# ATSAME51J18A register map
Vendor: Microchip Technology; Series: SAME51; File version: 0
CPU: CM4 r0p1, selectable endian, MPU, FPU, 3 interrupt priority bits
Registers are 32-bit, read-write, reset 0x0 unless marked. A register's access mark holds for its fields unless they carry their own. Offsets are from the block's base; [hi:lo] are bit positions; lines under a group give offsets from that group; {n}, {i} and the like mark numbered series; 'fields as' and 'values as' point back to an identical list.

## DMAC — Direct Memory Access Controller
Base 0x4100A000; register names take the prefix DMAC_
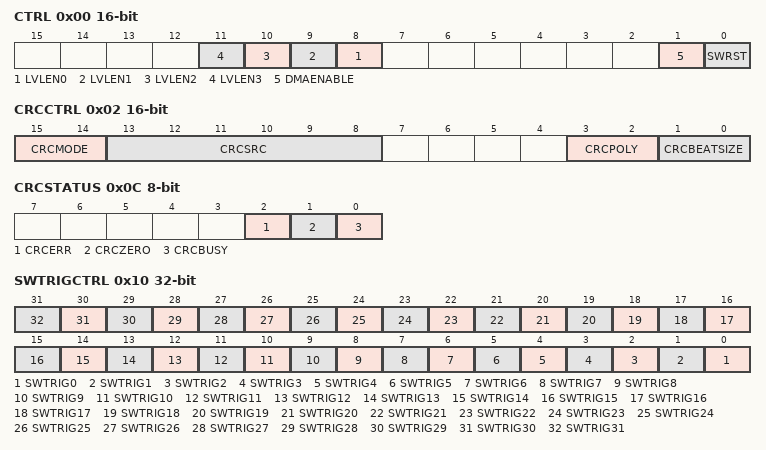
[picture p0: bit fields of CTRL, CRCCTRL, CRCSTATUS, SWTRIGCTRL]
0x00 CTRL 16-bit — Control
  [n+8] LVLEN{n} (n=0..3) — Priority Level {n} Enable
  [1] DMAENABLE
  [0] SWRST — Software Reset
0x02 CRCCTRL 16-bit — CRC Control
  [15:14] CRCMODE — CRC Operating Mode
    0=DEFAULT (Default operating mode); 2=CRCMON (Memory CRC monitor operating mode); 3=CRCGEN (Memory CRC generation operating mode)
  [13:8] CRCSRC — CRC Input Source
    0=DISABLE (CRC Disabled); 1=IO (I/O interface)
  [3:2] CRCPOLY — CRC Polynomial Type
    0=CRC16 (CRC-16 (CRC-CCITT)); 1=CRC32 (CRC32 (IEEE 802.3))
  [1:0] CRCBEATSIZE
    0=BYTE (8-bit bus transfer); 1=HWORD (16-bit bus transfer); 2=WORD (32-bit bus transfer)
0x04 CRCDATAIN — CRC Data Input
  [7:0] CRCDATAIN8 — CRC Data Input
  [15:0] CRCDATAIN16 — CRC Data Input
  [31:0] CRCDATAIN — CRC Data Input
0x08 CRCCHKSUM — CRC Checksum
  [15:0] CRCCHKSUM16 — CRC Checksum
  [31:0] CRCCHKSUM32 — CRC Checksum
0x0C CRCSTATUS 8-bit
  [2] CRCERR ro — CRC Error
  [1] CRCZERO ro
  [0] CRCBUSY write-1-clears — CRC Module Busy
0x0D DBGCTRL 8-bit — Debug Control
  [0] DBGRUN — Debug Run
0x10 SWTRIGCTRL — Software Trigger Control
  [n] SWTRIG{n} (n=0..31) — Channel {n} Software Trigger
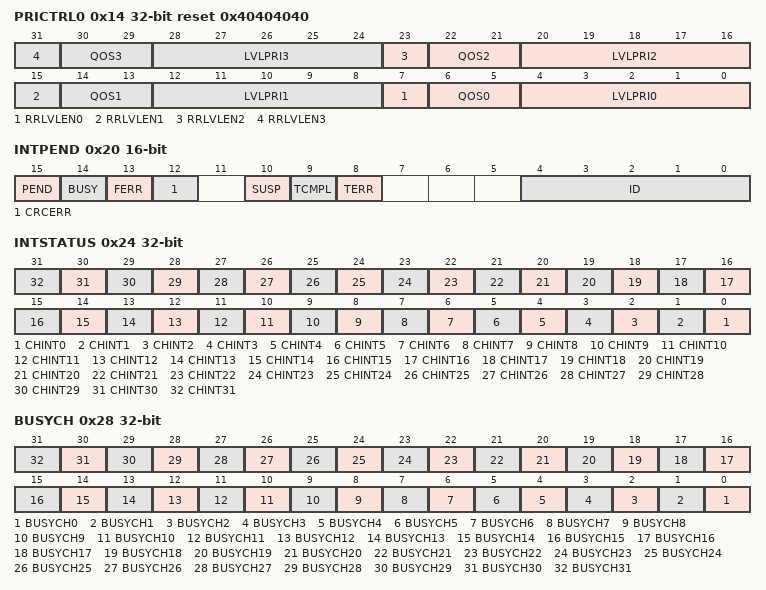
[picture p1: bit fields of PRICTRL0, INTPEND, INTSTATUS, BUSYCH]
0x14 PRICTRL0 reset 0x40404040 — Priority Control 0
  [8n+7] RRLVLEN{n} (n=0..3) — Level {n} Round-Robin Scheduling Enable
  [8n+6:8n+5] QOS{n} (n=0..3) — Level {n} Quality of Service
    0=REGULAR (Regular delivery); 1=SHORTAGE (Bandwidth shortage); 2=SENSITIVE (Latency sensitive); 3=CRITICAL (Latency critical)
  [8n+4:8n] LVLPRI{n} (n=0..3) — Level {n} Channel Priority Number
0x20 INTPEND 16-bit — Interrupt Pending
  [15] PEND ro — Pending
  [14] BUSY ro
  [13] FERR ro — Fetch Error
  [12] CRCERR write-1-clears — CRC Error
  [10] SUSP write-1-clears — Channel Suspend
  [9] TCMPL write-1-clears — Transfer Complete
  [8] TERR write-1-clears — Transfer Error
  [4:0] ID — Channel ID
0x24 INTSTATUS ro — Interrupt Status
  [n] CHINT{n} (n=0..31) — Channel {n} Pending Interrupt
0x28 BUSYCH ro — Busy Channels
  [n] BUSYCH{n} (n=0..31) — Busy Channel {n}
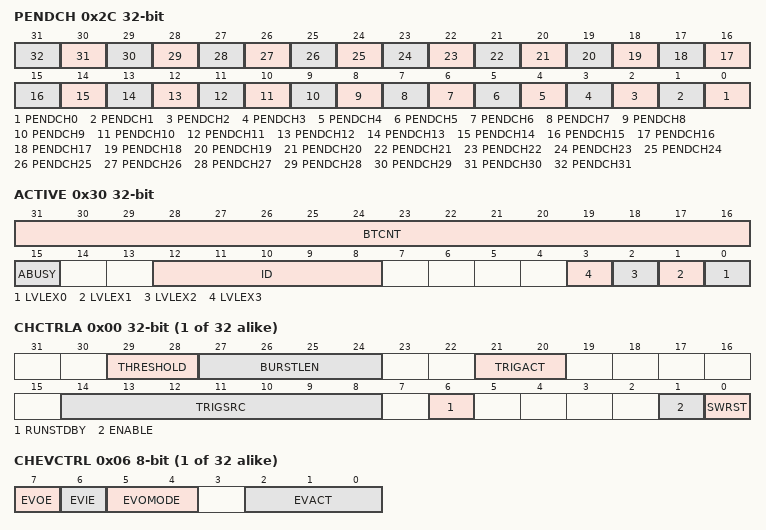
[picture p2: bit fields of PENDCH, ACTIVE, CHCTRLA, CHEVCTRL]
0x2C PENDCH ro — Pending Channels
  [n] PENDCH{n} (n=0..31) — Pending Channel {n}
0x30 ACTIVE ro — Active Channel and Levels
  [31:16] BTCNT — Active Channel Block Transfer Count
  [15] ABUSY — Active Channel Busy
  [12:8] ID — Active Channel ID
  [n] LVLEX{n} (n=0..3) — Level {n} Channel Trigger Request Executing
0x34 BASEADDR — Descriptor Memory Section Base Address
  [31:0] BASEADDR — Descriptor Memory Base Address
0x38 WRBADDR — Write-Back Memory Section Base Address
  [31:0] WRBADDR — Write-Back Memory Base Address
{0x40+0x10*i} CHANNEL[{i}] (i=0..31) group
  0x00 CHCTRLA — Channel n Control A
    [29:28] THRESHOLD — FIFO Threshold
      0=1BEAT (Destination write starts after each beat source address read); 1=2BEATS (Destination write starts after 2-beats source address read); 2=4BEATS (Destination write starts after 4-beats source address read); 3=8BEATS (Destination write starts after 8-beats source address read)
    [27:24] BURSTLEN — Burst Length
      0=SINGLE (Single-beat burst length); {v}={v+1}BEAT ({v+1}-beats burst length) (v=1..15)
    [21:20] TRIGACT — Trigger Action
      0=BLOCK (One trigger required for each block transfer); 2=BURST (One trigger required for each burst transfer); 3=TRANSACTION (One trigger required for each transaction)
    [14:8] TRIGSRC — Trigger Source
      0=DISABLE (Only software/event triggers); 1=RTC_TIMESTAMP (DMA RTC timestamp trigger); 2=DSU_DCC0 (DMAC ID for DCC0 register); 3=DSU_DCC1 (DMAC ID for DCC1 register); 4=SERCOM0_RX (Index of DMA RX trigger); 5=SERCOM0_TX (Index of DMA TX trigger); 6=SERCOM1_RX (Index of DMA RX trigger); 7=SERCOM1_TX (Index of DMA TX trigger); 8=SERCOM2_RX (Index of DMA RX trigger); 9=SERCOM2_TX (Index of DMA TX trigger); 10=SERCOM3_RX (Index of DMA RX trigger); 11=SERCOM3_TX (Index of DMA TX trigger); 12=SERCOM4_RX (Index of DMA RX trigger); 13=SERCOM4_TX (Index of DMA TX trigger); 14=SERCOM5_RX (Index of DMA RX trigger); 15=SERCOM5_TX (Index of DMA TX trigger); 16=SERCOM6_RX (Index of DMA RX trigger); 17=SERCOM6_TX (Index of DMA TX trigger); 18=SERCOM7_RX (Index of DMA RX trigger); 19=SERCOM7_TX (Index of DMA TX trigger); 20=CAN0_DEBUG (DMA CAN Debug Req); 21=CAN1_DEBUG (DMA CAN Debug Req); 22=TCC0_OVF (DMA overflow/underflow/retrigger trigger); {v}=TCC0_MC_{v-23} (Indexes of DMA Match/Compare triggers) (v=23..28); 29=TCC1__OVF_DMA (overflow/underflow/retrigger trigger); {v}=TCC1_MC_{v-30} (Indexes of DMA Match/Compare triggers) (v=30..33); 34=TCC2_OVF (DMA overflow/underflow/retrigger trigger); 35=TCC2_MC_0 (Indexes of DMA Match/Compare triggers); 36=TCC2_MC_1 (Indexes of DMA Match/Compare triggers); 37=TCC2_MC_2 (Indexes of DMA Match/Compare triggers); 38=TCC3_OVF (DMA overflow/underflow/retrigger trigger); 39=TCC3_MC_0 (Indexes of DMA Match/Compare triggers); 40=TCC3_MC_1 (Indexes of DMA Match/Compare triggers); 41=TCC4_OVF (DMA overflow/underflow/retrigger trigger); 42=TCC4_MC_0 (Indexes of DMA Match/Compare triggers); 43=TCC4_MC_1 (Indexes of DMA Match/Compare triggers); 44=TC0_OVF (Indexes of DMA Overflow trigger); 45=TC0_MC_0 (Indexes of DMA Match/Compare triggers); 46=TC0_MC_1 (Indexes of DMA Match/Compare triggers); 47=TC1_OVF (Indexes of DMA Overflow trigger); 48=TC1_MC_0 (Indexes of DMA Match/Compare triggers); 49=TC1_MC_1 (Indexes of DMA Match/Compare triggers); 50=TC2_OVF (Indexes of DMA Overflow trigger); 51=TC2_MC_0 (Indexes of DMA Match/Compare triggers); 52=TC2_MC_1 (Indexes of DMA Match/Compare triggers); 53=TC3_OVF (Indexes of DMA Overflow trigger); 54=TC3_MC_0 (Indexes of DMA Match/Compare triggers); 55=TC3_MC_1 (Indexes of DMA Match/Compare triggers); 56=TC4_OVF (Indexes of DMA Overflow trigger); 57=TC4_MC_0 (Indexes of DMA Match/Compare triggers); 58=TC4_MC_1 (Indexes of DMA Match/Compare triggers); 59=TC5_OVF (Indexes of DMA Overflow trigger); 60=TC5_MC_0 (Indexes of DMA Match/Compare triggers); 61=TC5_MC_1 (Indexes of DMA Match/Compare triggers); 62=TC6_OVF (Indexes of DMA Overflow trigger); 63=TC6_MC_0 (Indexes of DMA Match/Compare triggers); 64=TC6_MC_1 (Indexes of DMA Match/Compare triggers); 65=TC7_OVF (Indexes of DMA Overflow trigger); 66=TC7_MC_0 (Indexes of DMA Match/Compare triggers); 67=TC7_MC_1 (Indexes of DMA Match/Compare triggers); 68=ADC0_RESRDY (index of DMA RESRDY trigger); 69=ADC0_SEQ (Index of DMA SEQ trigger); 70=ADC1_RESRDY (Index of DMA RESRDY trigger); 71=ADC1_SEQ (Index of DMA SEQ trigger); 72=DAC_EMPTY_0 (DMA DAC Empty Req); 73=DAC_EMPTY_1 (DMA DAC Empty Req); 74=DAC_RESRDY_0 (DMA DAC Result Ready Req); 75=DAC_RESRDY_1 (DMA DAC Result Ready Req); 76=I2S_RX_0 (Indexes of DMA RX triggers); 77=I2S_RX_1 (Indexes of DMA RX triggers); 78=I2S_TX_0 (Indexes of DMA TX triggers); 79=I2S_TX_1 (Indexes of DMA TX triggers); 80=PCC_RX (Indexes of PCC RX trigger); 81=AES_WR (DMA DATA Write trigger); 82=AES_RD (DMA DATA Read trigger); 83=QSPI_RX (Indexes of QSPI RX trigger); 84=QSPI_TX (Indexes of QSPI TX trigger)
    [6] RUNSTDBY — Channel Run in Standby
    [1] ENABLE — Channel Enable
    [0] SWRST — Channel Software Reset
  0x04 CHCTRLB 8-bit — Channel n Control B
    [1:0] CMD — Software Command
      0=NOACT (No action); 1=SUSPEND (Channel suspend operation); 2=RESUME (Channel resume operation)
  0x05 CHPRILVL 8-bit — Channel n Priority Level
    [1:0] PRILVL — Channel Priority Level
      0=LVL0 (Channel Priority Level 0 (Lowest Level)); 1=LVL1 (Channel Priority Level 1); 2=LVL2 (Channel Priority Level 2); 3=LVL3 (Channel Priority Level 3 (Highest Level))
  0x06 CHEVCTRL 8-bit — Channel n Event Control
    [7] EVOE — Channel Event Output Enable
    [6] EVIE — Channel Event Input Enable
    [5:4] EVOMODE — Channel Event Output Mode
      0=DEFAULT (Block event output selection. Refer to BTCTRL.EVOSEL for available selections.); 1=TRIGACT (Ongoing trigger action)
    [2:0] EVACT — Channel Event Input Action
      0=NOACT (No action); 1=TRIG (Transfer and periodic transfer trigger); 2=CTRIG (Conditional transfer trigger); 3=CBLOCK (Conditional block transfer); 4=SUSPEND (Channel suspend operation); 5=RESUME (Channel resume operation); 6=SSKIP (Skip next block suspend action); 7=INCPRI (Increase priority)
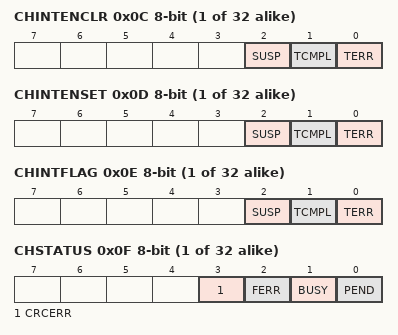
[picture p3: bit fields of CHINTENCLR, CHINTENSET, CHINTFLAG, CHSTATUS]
  0x0C CHINTENCLR 8-bit — Channel n Interrupt Enable Clear
    [2] SUSP — Channel Suspend Interrupt Enable
    [1] TCMPL — Channel Transfer Complete Interrupt Enable
    [0] TERR — Channel Transfer Error Interrupt Enable
  0x0D CHINTENSET 8-bit — Channel n Interrupt Enable Set
    fields as CHANNEL[0].CHINTENCLR
  0x0E CHINTFLAG 8-bit — Channel n Interrupt Flag Status and Clear
    [2] SUSP write-1-clears — Channel Suspend
    [1] TCMPL write-1-clears — Channel Transfer Complete
    [0] TERR write-1-clears — Channel Transfer Error
  0x0F CHSTATUS 8-bit — Channel n Status
    [3] CRCERR write-1-clears — Channel CRC Error
    [2] FERR ro — Channel Fetch Error
    [1] BUSY ro — Channel Busy
    [0] PEND ro — Channel Pending

## Notices in the file
Copyright (c) 2017 Microchip Technology Inc.
SPDX-License-Identifier: Apache-2.0
Licensed under the Apache License, Version 2.0 (the "License");
you may not use this file except in compliance with the License.
You may obtain a copy of the License at
http://www.apache.org/licenses/LICENSE-2.0
Unless required by applicable law or agreed to in writing, software
distributed under the License is distributed on an "AS IS" BASIS,
WITHOUT WARRANTIES OR CONDITIONS OF ANY KIND, either express or implied.
See the License for the specific language governing permissions and
limitations under the License.
